# DDRSS0_SS_CFG register map
Vendor: Texas Instruments
Peripheral module from a debugger description file (folder am65x).
Registers are 32-bit, read-only, reset 0x0 unless marked. A register's access mark holds for its fields unless they carry their own. Offsets are as the file gives them; lines under a group give offsets from that group; [hi:lo] are bit positions; {n}, {i} and the like mark numbered series; 'fields as' and 'values as' point back to an identical list; <NAME> marks a mode.

## DDRSS0_SS_CFG
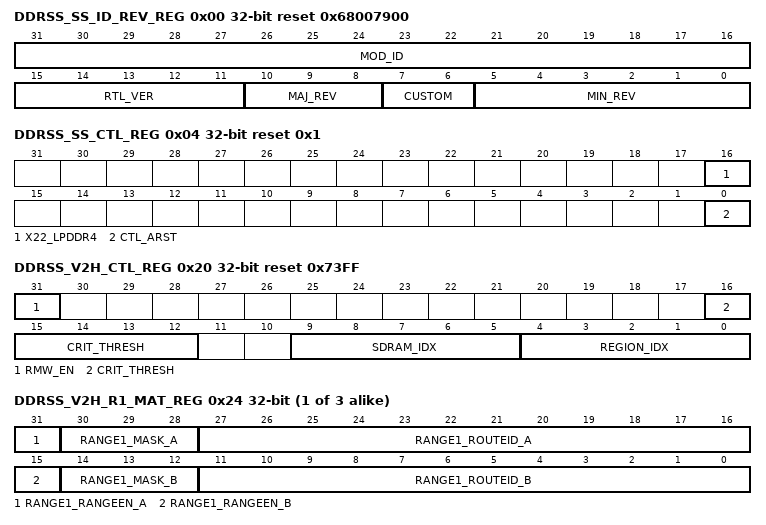
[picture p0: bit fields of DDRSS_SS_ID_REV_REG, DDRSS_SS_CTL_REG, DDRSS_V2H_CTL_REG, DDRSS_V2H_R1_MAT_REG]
0x00 DDRSS_SS_ID_REV_REG reset 0x68007900 — The Subsystem ID and Revision Register contains the module ID, major, and minor revisions for the subsystem.
  [31:16] MOD_ID — Module ID
  [15:11] RTL_VER — RTL version
  [10:8] MAJ_REV — Major revision
  [7:6] CUSTOM
  [5:0] MIN_REV — Minor revision
0x04 DDRSS_SS_CTL_REG rw reset 0x1 — The Subsystem Control Register contains fields for control functions required for submodules in the subsystem.
  [16] X22_LPDDR4 — Write 0x1 to enable x22 LPDDR4 mode: 16-bit data plus 6-bit ECC with LPDDR4
  [0] CTL_ARST — DDR controller and DDR PHY requires reset sequencing through software.Write 0 to deassert resets to the controller and PHY during initialization procedure. Write 1 to assert the resets.NOTE:This bit must only be used for the reset deassertion sequence during power-up. It must not be used for reset assertion after power-up, since it only resets the DDR controller and PHY, and does not reset the MSMC2DDR bridge or other DDRSS submodules. The MSMC2DDR bridge and the DDR controller use a credit based scheme for the HIF interface. Resetting just the DDR controller and not resetting the MSMC2DDR bridge will cause credit counts in the bridge to go out of sync with respect to the DDR controller, potentially causing a hang.
0x20 DDRSS_V2H_CTL_REG rw reset 0x73FF — The MSMC2DDR Bridge Control register contains control functions required for the MSMC2DDR bridge.
  [31] RMW_EN — Enables the ability for the MSMC2DDR bridge to create RMW operations for the DDR controller for sub DDR bus-width quanta writes.That is if a write occurs and the byte enables do not cover an entire DDR bus-width quanta a RMW operation is requested. This must be set to 1 if ECC and/or DBI is enabled in the DDR controller.
  [16:12] CRIT_THRESH — Critical threshold.The MSMC2DDR bridge will give back global credits on the VBUSM.C interface only if the available credits on the LPR/NPW queues in the DDR controller are greater than this value. It must be ensured that this value is less than the SCHED.lpr_num_entries+1 in the DDR controller. The reset values of this field and SCHED.lpr_num_entries are optimal however, they can be changed for better traffic shaping.
  [9:5] SDRAM_IDX — SDRAM Index = log2(connected SDRAM size) - 16.The sdram_idx describes the number of address bits minus 16 that are used to determine the mask used to detect memory rollover and prevent aliasing and false coherency issues.
  [4:0] REGION_IDX — Region Index = log2(CBA region size) - 16.The region_idx describes the number of address bits minus 16 that are used to determine the mask used to detect memory rollover and prevent aliasing and false coherency issues.
{0x20+4i} DDRSS_V2H_R{i}_MAT_REG rw (i=1..3) — The Range {i} Match Register allows a single master to a range of masters to change their priority mapping. This allows selective masters to be increased or decreased in effective priority. Range {i} Match Register uses the associated Range {i} Priority Map Register. The highest Range Match Register will take priority and will be used in case of multiple range matches.
  [31] RANGE{i}_RANGEEN_A — The range{i}_rangeen_a enables the RouteId AND'd with range{i}_mask_a to match the range{i}_routeid_a
  [30:28] RANGE{i}_MASK_A — The range{i}_mask_a allows a number of least significant bits to be ignored prior to the match of the routeid_a
  [27:16] RANGE{i}_ROUTEID_A — The range{i}_routeid_a is the value that is compared to the RouteId arriving on the command interface
  [15] RANGE{i}_RANGEEN_B — The range{i}_rangeen_b enables the RouteId AND'd with range{i}_mask_b to match the range{i}_routeid_b
  [14:12] RANGE{i}_MASK_B — The range{i}_mask_b allows a number of least significant bits to be ignored prior to the match of the routeid_b
  [11:0] RANGE{i}_ROUTEID_B — The range{i}_routeid_b is the value that is compared to the RouteId arriving on the command interface
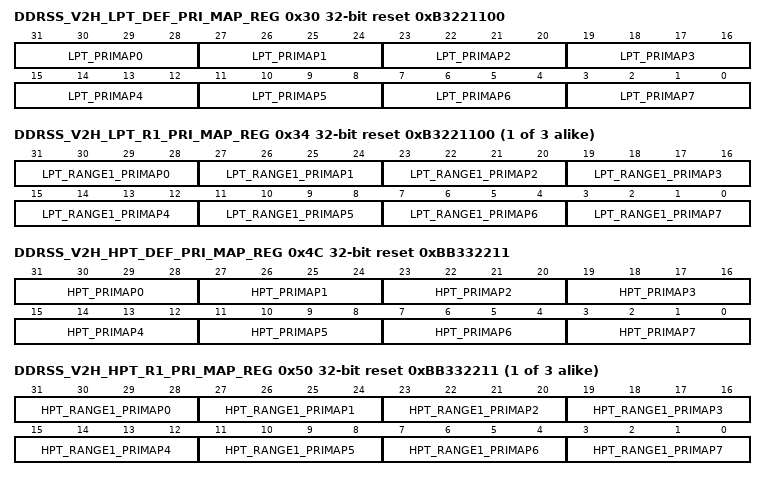
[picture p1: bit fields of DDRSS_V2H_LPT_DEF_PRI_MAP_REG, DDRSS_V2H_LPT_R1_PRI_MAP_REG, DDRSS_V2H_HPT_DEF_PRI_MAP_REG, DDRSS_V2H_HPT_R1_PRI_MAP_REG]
0x30 DDRSS_V2H_LPT_DEF_PRI_MAP_REG rw reset 0xB3221100 — The LPT Default Priority Mapping Register is used for accesses arriving on the Low Priority Thread on the VBUSM.C interface. The lpt_primapX is defined {HPR,cos_level} where the HPR (High Priority Read) bit will force a high priority read and the cos_level is 1-3 where 0 is Low Priority Read/Normal Priority Write (LPR/NPW). The cos_level 1-3 will apply the latency for the associated Class Latency Register to the HIF using Variable Priority Read/Write (VPR/VPW).
  [31-4n:28-4n] LPT_PRIMAP{n} (n=0..7) — The field contains the HPR and cos_level for the VBUSM.C priority {n}
{0x30+4i} DDRSS_V2H_LPT_R{i}_PRI_MAP_REG rw reset 0xB3221100 (i=1..3) — The LPT Range {i} Priority Mapping Register is used to map the inbound priority on the Low Priority Thread to the latency class when a RouteId match {i} occurs. This allows the CoS level to be changed from the LPT Default Priority Mapping value.
  [31-4n:28-4n] LPT_RANGE{i}_PRIMAP{n} (n=0..7) — The field contains the HPR and cos_level for the VBUSM.C priority {n} for range match {i}
{0x3C+4i} DDRSS_V2H_C{i}_LAT_REG rw reset 0x3FF (i=1..3) — The Class {i} Latency Register is used to control how long a command may stay in the memory controller before it is executed without regard to performance impact of the DDR. The user must be careful when using small values as the smaller the value are, the more DDR thrashing could occur reducing overall system throughput.
  [10:0] CLASS{i}_LATENCY — The field contains the latency given in ddrss_ctl_clk cycles when the resulting priority map matches this class number.A value of zero causes that class of service to be disabled.
0x4C DDRSS_V2H_HPT_DEF_PRI_MAP_REG rw reset 0xBB332211 — The HPT Default Priority Mapping Register is used for accesses arriving on the High Priority Thread on the VBUSM.C interface. The hpt_primapX is defined {HPR,cos_level} where the HPR (High Priority Read) bit will force a high priority read and the cos_level is 1-3 where 0 is Low Priority Read/Normal Priority Write (LPR/NPW). The cos_level 1-3 will apply the latency for the associated Class Latency Register to the HIF using Variable Priority Read/Write (VPR/VPW).
  [31-4n:28-4n] HPT_PRIMAP{n} (n=0..7) — The field contains the HPR and cos_level for the VBUSM.C priority {n}
{0x4C+4i} DDRSS_V2H_HPT_R{i}_PRI_MAP_REG rw reset 0xBB332211 (i=1..3) — The HPT Range {i} Priority Mapping Register is used to map the inbound priority on the High Priority Thread to the latency class when a RouteId match {i} occurs. This allows the CoS level to be changed from the HPT Default Priority Mapping value.
  [31-4n:28-4n] HPT_RANGE{i}_PRIMAP{n} (n=0..7) — The field contains the HPR and cos_level for the VBUSM.C priority {n} for range match {i}
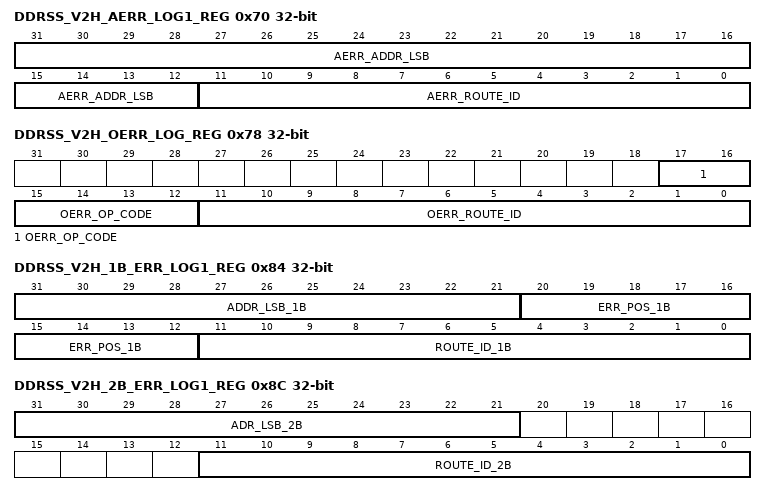
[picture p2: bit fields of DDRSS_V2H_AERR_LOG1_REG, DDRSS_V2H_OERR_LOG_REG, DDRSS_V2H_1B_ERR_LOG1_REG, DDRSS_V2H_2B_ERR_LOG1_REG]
0x70 DDRSS_V2H_AERR_LOG1_REG access not given — The Address Error Log 1 register displays the routeID and lsb of the address for the first VBUSM.C command that was outside the programmed addressing range. Writing a 0x1 will clear all fields. Writing any other value has no effect. The Address Error Log 2 register will also be cleared upon writing this register.
  [31:12] AERR_ADDR_LSB — Address[19:0] of the VBUSM.C command (access RW1C)
  [11:0] AERR_ROUTE_ID — RouteID of the VBUSM.C write command (access RW1C)
0x74 DDRSS_V2H_AERR_LOG2_REG — The Address Error Log 2 registers displays the msb of the address for the first VBUSM.C command that was outside the programmed addressing range. This register will be cleared upon writing the Address Error Log 1 register.
  [27:0] AERR_ADDR_MSB — Address[47:20] of the VBUSM.C command
0x78 DDRSS_V2H_OERR_LOG_REG access not given — The Opcode Error Log register displays the routeID and opcode for the first VBUSM.C command that had an unsupported opcode. Writing a 0x1 will clear all fields. Writing any other value has no effect.
  [17:12] OERR_OP_CODE — Opcode of the VBUSM.C command (access RW1C)
  [11:0] OERR_ROUTE_ID — RouteID of the VBUSM.C command (access RW1C)
0x80 DDRSS_V2H_1B_ERR_CNT_REG access not given — MSMC2DDR Bridge 1-Bit EDC Error Count Register
  [31:0] EDC_1B_ERR_CNT — 32-bit counter that displays number of 1-bit EDC errors on write data received on the VBUSM.C interface.Writing a 0x1 will clear this count. Writing any other value has no effect. (access RW1C)
0x84 DDRSS_V2H_1B_ERR_LOG1_REG access not given — The 1-Bit EDC Error Log 1 register displays the routeID, error position, and lsb of the address for the first VBUSM.C write that incurred 1-bit EDC error. Writing a 0x1 will clear all fields. Writing any other value has no effect. The 1-Bit EDC Error Log 2 register will also be cleared upon writing this register.
  [31:21] ADDR_LSB_1B — Address[15:5] of the VBUSM.C write command (access RW1C)
  [20:12] ERR_POS_1B — Bit error position (access RW1C)
  [11:0] ROUTE_ID_1B — RouteID of the VBUSM.C write command (access RW1C)
0x88 DDRSS_V2H_1B_ERR_LOG2_REG — The 1-Bit EDC Error Log 2 registers displays the msb of the address for the first VBUSM.C write that incurred 1-bit EDC error. This register will be cleared upon writing the 1-Bit EDC Error Log 1 register.
  [31:0] ADDR_MSB_1B — Address[47:16] of the VBUSM.C write command
0x8C DDRSS_V2H_2B_ERR_LOG1_REG access not given — The 2-Bit EDC Error Log 1 register displays the routeID, error position, and address of the first VBUSM.C write that incurs 2-bit EDC error. Writing a 0x1 clear all fields. Writing any other value has no effect. The 2-Bit EDC Error Log 2 register will also be cleared upon writing this register.
  [31:21] ADR_LSB_2B — Address[15:5] of the VBUSM.C write command (access RW1C)
  [11:0] ROUTE_ID_2B — RouteID of the VBUSM.C write command (access RW1C)
0x90 DDRSS_V2H_2B_ERR_LOG2_REG — The 2-Bit EDC Error Log 1 register displays the address of the first VBUSM.C write that incurs 2-bit EDC error. This register will be cleared upon writing the 2-Bit EDC Error Log 1 register.
  [31:0] ADR_MSB_2B — Address[47:16] of the VBUSM.C write command
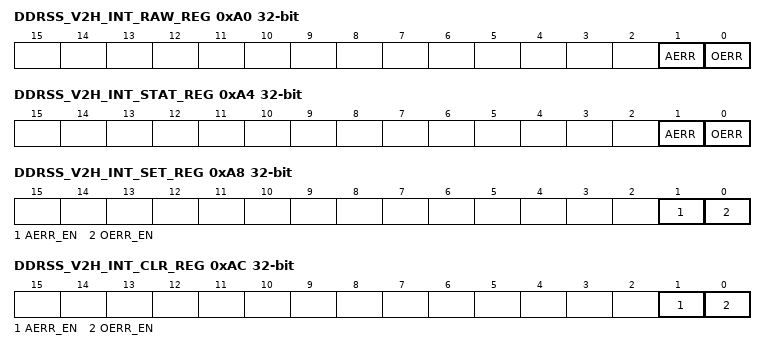
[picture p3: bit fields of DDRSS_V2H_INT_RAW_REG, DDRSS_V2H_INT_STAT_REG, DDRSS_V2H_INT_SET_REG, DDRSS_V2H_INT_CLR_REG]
0xA0 DDRSS_V2H_INT_RAW_REG access not given — MSMC2DDR Bridge Interrupt Raw Status Register
  [1] AERR — Raw status of MSMC2DDR bridge interrupt for VBUSM.C address outside the programmed range.Write 1 to set the (raw) status, mostly for debug. Writing a 0 has no effect. (access RW1S)
  [0] OERR — Raw status of MSMC2DDR bridge interrupt for VBUSM.C unsupported opcode.Write 1 to set the (raw) status, mostly for debug. Writing a 0 has no effect. (access RW1S)
0xA4 DDRSS_V2H_INT_STAT_REG access not given — MSMC2DDR Bridge Interrupt Status Register
  [1] AERR — Enabled status of MSMC2DDR bridge interrupt for VBUSM.C address outside the programmed range.Write 1 to clear the status after interrupt has been serviced (raw status gets cleared, i.e. even if not enabled). Writing a 0 has no effect. (access RW1C)
  [0] OERR — Enabled status of MSMC2DDR bridge interrupt for VBUSM.C unsupported opcode.Write 1 to clear the status after interrupt has been serviced (raw status gets cleared, i.e. even if not enabled). Writing a 0 has no effect. (access RW1C)
0xA8 DDRSS_V2H_INT_SET_REG access not given — MSMC2DDR Bridge Interrupt Enable Set Register
  [1] AERR_EN — Enable set for MSMC2DDR bridge interrupt for VBUSM.C address outside the programmed range.Writing a 1 will enable the interrupt, and set this bit as well as the corresponding Interrupt Enable Clear Register. Writing a 0 has no effect. (access RW1S)
  [0] OERR_EN — Enable set for MSMC2DDR bridge interrupt for VBUSM.C unsupported opcode.Writing a 1 will enable the interrupt, and set this bit as well as the corresponding Interrupt Enable Clear Register. Writing a 0 has no effect. (access RW1S)
0xAC DDRSS_V2H_INT_CLR_REG access not given — MSMC2DDR Bridge Interrupt Enable Clear Register
  [1] AERR_EN — Enable clear for MSMC2DDR bridge interrupt for VBUSM.C address outside the programmed range.Writing a 1 will disable the interrupt, and clear this bit as well as the corresponding Interrupt Enable Set Register. Writing a 0 has no effect. (access RW1C)
  [0] OERR_EN — Enable clear for MSMC2DDR bridge interrupt for VBUSM.C unsupported opcode.Writing a 1 will disable the interrupt, and clear this bit as well as the corresponding Interrupt Enable Set Register. Writing a 0 has no effect. (access RW1C)
0xB0 DDRSS_V2H_EOI_REG wo — MSMC2DDR Bridge End of Interrupt Register The EOI register is used to re-trigger the pulse interrupt signal to ensure that any nested interrupt events are serviced. The software interrupt handler must write to the EOI register at the end of the current interrupt processing routine, so that new events can re-trigger the pulse interrupt signal again. For level interrupt signals the EOI register is not functional and must not be used.
  [1:0] EOI — Software End Of Interrupt (EOI) control.Write 0 for MSMC2DDR bridge aerr/oerr interrupt. Write 1 for MSMC2DDR bridge 1-bit EDC interrupt. Write 2 for MSMC2DDR bridge 2-bit EDC interrupt. This field always reads 0 (no EOI memory).
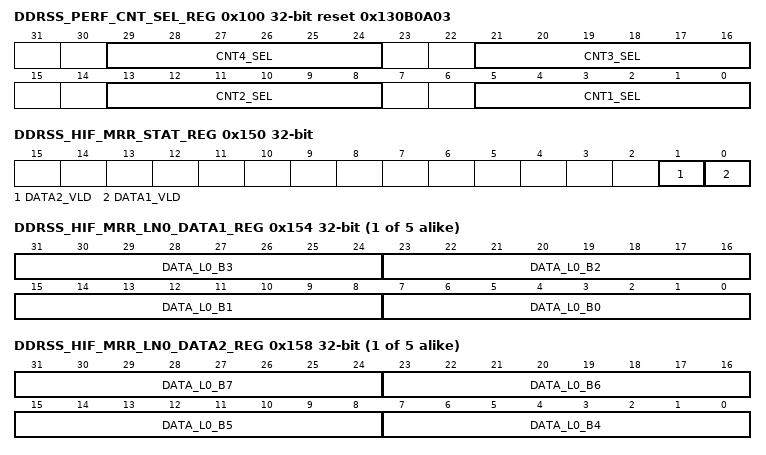
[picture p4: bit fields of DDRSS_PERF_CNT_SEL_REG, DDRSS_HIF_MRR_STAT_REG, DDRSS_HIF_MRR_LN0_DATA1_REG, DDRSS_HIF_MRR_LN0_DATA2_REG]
0x100 DDRSS_PERF_CNT_SEL_REG rw reset 0x130B0A03 — The Performance Counter Select register is used to select the statistic type to be counted in the corresponding Performance Counter register.
  [8n-3:8n-8] CNT{n}_SEL (n=1..4) — Statistic select for Performance Counter {n} register.0x0 = Counts Read or Write commands send to the DDR controller. 0x1 = Counts every Write command send to the DDR controller. 0x2 = Counts every Read command send to the DDR controller. 0x3 = Counts every RMW command send to the DDR controller. 0x4 = Counts every High-Priority Read command send to the DDR controller. 0x6 = Counts every read data beat transfer on the DFI interface coming from SDRAM. 0x7 = Counts every High Priority Read transaction that is scheduled when the High Priority Queue is in Critical state in the DDR controller. 0x8 = Counts every Low Priority Read transaction that is scheduled when the Low Priority Queue is in Critical state in the DDR controller. 0x9 = Counts every Write transaction that is scheduled when the Write Queue is in Critical state in the DDR controller. 0xA = Counts every Activate that is issued for commands going through CAM in the DDR controller. 0xB = Counts every Read or Write that is issued for commands going through CAM in the DDR controller. 0xC = Counts every Read Activate that is issued for commands going through CAM in the DDR controller. 0xD = Counts every Read that is issued for commands going through CAM in the DDR controller. 0xE = Counts every Write that is issued for commands going through CAM in the DDR controller. 0xF = Counts every Masked Write that is issued for commands going through CAM in the DDR controller. 0x10 = Counts every Precharge that is issued by the DDR controller. 0x11 = Counts every Precharge that is issued by the DDR controller for Read or Write commands. 0x12 = Counts every Precharge that is issued by the DDR controller due to requests other than Read or Write (for eg: Refresh, ZQ Calib, MRW, MRR, tRAS(max)). 0x13 = Counts every Read to Write and Write to Read bus-turn-around that happens in the DDR controller. 0x14 = Counts every Write Combine operation that happens in the DDR controller. 0x15 = Counts every Write-after-Read collision tkhat happens in the DDR controller. 0x16 = Counts every Read-after-Write collision that happens in the DDR controller. 0x17 = Counts every Write-after-Write collision that happens in the DDR controller. Is valid only when Write Combine is turned off. 0x18 = Counts every entry into Self-Refresh mode. 0x19 = Counts every entry into PowerDown mode. 0x1A = Counts every entry into Deep-PowerDown mode. 0x1B = Counts every entry into Maximum Power Savings mode. 0x1C = Counts every cycle for which the DDR controller stays in Self-Refresh mode. 0x1D = Counts every Refresh command that is issued by the DDR controller. 0x1E = Counts every Load Mode operation (MRW or MRR) that is issued by the DDR controller. 0x1F = Counts every ZQ Calib Long command that is issued by the DDR controller. 0x20 = Counts every ZQ Calib Short command that is issued by the DDR controller. 0x21-0x2F = Reserved
{0x100+4i} DDRSS_PERF_CNT{i}_REG (i=1..4) — Performance Counter {i} Register
  [31:0] CNT{i} — Soft 32-bit counter that can be configured as specified in the Performance Counter Select Register.
0x150 DDRSS_HIF_MRR_STAT_REG access not given — The HIF MRR Status register is used in conjunction with the HIF MRR Lane Data registers for Multi Purpose Register (MPR) read for DDR4 and Mode Register Read (MRR) for LPDDR4. The HIF MRR Lane Data registers display the data sent by the SDRAM as a result of the MPR or MRR.
  [1] DATA2_VLD ro — Value of 1 indicates HIF MRR Data 2 registers have valid data.This is used for MPR (DDR4) and MRR (LPDDR4).
  [0] DATA1_VLD — Value of 1 indicates HIF MRR Data 1 registers have valid data.This is used for MPR (DDR4) and MRR (LPDDR4). Writing a 0x1 will clear this field and data2_vld field, and all the HIF MRR Data registers. Writing any other value has no effect. (access RW1C)
{0x154+8i} DDRSS_HIF_MRR_LN{i}_DATA1_REG (i=0..4) — The HIF MRR Lane {i} Data 1 register displays the data sent by the SDRAM on byte lane {i} as a result of the MPR or MRR. The beat represents the position of the data in the SDRAM burst.
  [8n+7:8n] DATA_L{i}_B{n} (n=0..3) — Data for byte lane {i} burst beat {n}
{0x158+8i} DDRSS_HIF_MRR_LN{i}_DATA2_REG (i=0..4) — The HIF MRR Lane {i} Data 2 register displays the data sent by the SDRAM on byte lane {i} as a result of the MPR or MRR. The beat represents the position of the data in the SDRAM burst.
  [8n-25:8n-32] DATA_L{i}_B{n} (n=4..7) — Data for byte lane {i} burst beat {n}
